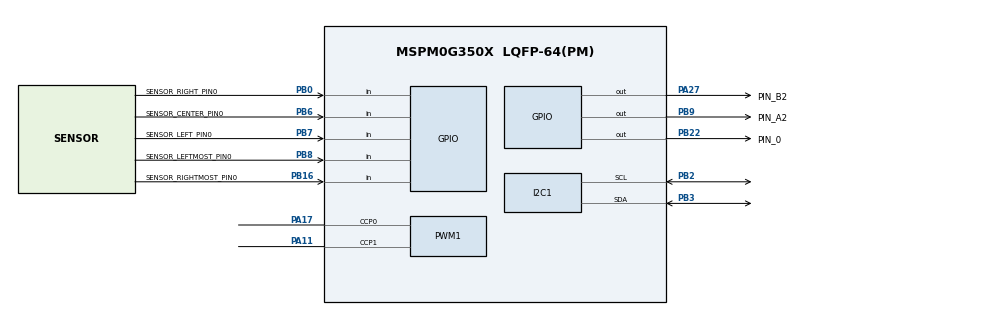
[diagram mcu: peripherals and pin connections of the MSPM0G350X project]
/**
 * @cliArgs --device "MSPM0G350X" --part "Default" --package "LQFP-64(PM)" --product "mspm0_sdk@2.05.01.00"
 * @versions {"tool":"1.24.0+4110"}
 */

/**
 * Import the modules used in this configuration.
 */
const GPIO   = scripting.addModule("/ti/driverlib/GPIO", {}, false);
const GPIO1  = GPIO.addInstance();
const GPIO2  = GPIO.addInstance();
const GPIO3  = GPIO.addInstance();
const GPIO4  = GPIO.addInstance();
const GPIO5  = GPIO.addInstance();
const GPIO6  = GPIO.addInstance();
const I2C    = scripting.addModule("/ti/driverlib/I2C", {}, false);
const I2C1   = I2C.addInstance();
const PWM    = scripting.addModule("/ti/driverlib/PWM", {}, false);
const PWM1   = PWM.addInstance();
const SYSCTL = scripting.addModule("/ti/driverlib/SYSCTL");

/**
 * Write custom configuration values to the imported modules.
 */
const divider7       = system.clockTree["PLL_PDIV"];
divider7.divideValue = 2;

const divider9       = system.clockTree["UDIV"];
divider9.divideValue = 2;

const multiplier2         = system.clockTree["PLL_QDIV"];
multiplier2.multiplyValue = 5;

const mux8       = system.clockTree["HSCLKMUX"];
mux8.inputSelect = "HSCLKMUX_SYSPLL2X";

GPIO1.$name                          = "GPIO_LED";
GPIO1.associatedPins[0].$name        = "PIN_0";
GPIO1.associatedPins[0].assignedPort = "PORTB";
GPIO1.associatedPins[0].assignedPin  = "22";
GPIO1.associatedPins[0].pin.$assign  = "PB22";

const Board = scripting.addModule("/ti/driverlib/Board", {}, false);

GPIO2.$name                          = "GPIO_SENSOR";
GPIO2.associatedPins.create(5);
GPIO2.associatedPins[0].direction    = "INPUT";
GPIO2.associatedPins[0].$name        = "SENSOR_LEFTMOST_PIN0";
GPIO2.associatedPins[0].assignedPort = "PORTB";
GPIO2.associatedPins[0].assignedPin  = "8";
GPIO2.associatedPins[0].pin.$assign  = "PB8";
GPIO2.associatedPins[1].direction    = "INPUT";
GPIO2.associatedPins[1].$name        = "SENSOR_LEFT_PIN0";
GPIO2.associatedPins[1].assignedPort = "PORTB";
GPIO2.associatedPins[1].assignedPin  = "7";
GPIO2.associatedPins[1].pin.$assign  = "PB7";
GPIO2.associatedPins[2].direction    = "INPUT";
GPIO2.associatedPins[2].$name        = "SENSOR_CENTER_PIN0";
GPIO2.associatedPins[2].assignedPort = "PORTB";
GPIO2.associatedPins[2].assignedPin  = "6";
GPIO2.associatedPins[2].pin.$assign  = "PB6";
GPIO2.associatedPins[3].$name        = "SENSOR_RIGHT_PIN0";
GPIO2.associatedPins[3].direction    = "INPUT";
GPIO2.associatedPins[3].assignedPort = "PORTB";
GPIO2.associatedPins[3].assignedPin  = "0";
GPIO2.associatedPins[3].pin.$assign  = "PB0";
GPIO2.associatedPins[4].direction    = "INPUT";
GPIO2.associatedPins[4].$name        = "SENSOR_RIGHTMOST_PIN0";
GPIO2.associatedPins[4].assignedPort = "PORTB";
GPIO2.associatedPins[4].assignedPin  = "16";
GPIO2.associatedPins[4].pin.$assign  = "PB16";

GPIO3.$name                          = "GPIO_ENCODER_L";
GPIO3.associatedPins.create(2);
GPIO3.associatedPins[0].$name        = "PIN_A1";
GPIO3.associatedPins[0].assignedPort = "PORTA";
GPIO3.associatedPins[0].assignedPin  = "26";
GPIO3.associatedPins[1].$name        = "PIN_B1";
GPIO3.associatedPins[1].assignedPort = "PORTB";
GPIO3.associatedPins[1].assignedPin  = "24";

GPIO4.$name                          = "GPIO_ENCODER_R";
GPIO4.associatedPins.create(2);
GPIO4.associatedPins[0].$name        = "PIN_A2";
GPIO4.associatedPins[0].assignedPort = "PORTB";
GPIO4.associatedPins[0].assignedPin  = "9";
GPIO4.associatedPins[0].pin.$assign  = "PB9";
GPIO4.associatedPins[1].$name        = "PIN_B2";
GPIO4.associatedPins[1].assignedPort = "PORTA";
GPIO4.associatedPins[1].assignedPin  = "27";
GPIO4.associatedPins[1].pin.$assign  = "PA27";

GPIO5.$name                          = "GPIO_6612";
GPIO5.associatedPins.create(5);
GPIO5.associatedPins[0].$name        = "AIN_2";
GPIO5.associatedPins[0].assignedPort = "PORTA";
GPIO5.associatedPins[0].assignedPin  = "28";
GPIO5.associatedPins[1].$name        = "AIN_1";
GPIO5.associatedPins[1].assignedPort = "PORTA";
GPIO5.associatedPins[1].assignedPin  = "31";
GPIO5.associatedPins[2].$name        = "STBY";
GPIO5.associatedPins[2].assignedPort = "PORTB";
GPIO5.associatedPins[2].initialValue = "SET";
GPIO5.associatedPins[2].assignedPin  = "12";
GPIO5.associatedPins[3].$name        = "BIN_1";
GPIO5.associatedPins[3].assignedPort = "PORTA";
GPIO5.associatedPins[3].assignedPin  = "12";
GPIO5.associatedPins[4].$name        = "BIN_2";
GPIO5.associatedPins[4].assignedPort = "PORTA";
GPIO5.associatedPins[4].assignedPin  = "13";

GPIO6.$name                              = "GPIO_BUTTON";
GPIO6.associatedPins.create(2);
GPIO6.associatedPins[0].$name            = "PIN_1";
GPIO6.associatedPins[0].direction        = "INPUT";
GPIO6.associatedPins[0].assignedPort     = "PORTB";
GPIO6.associatedPins[0].assignedPin      = "21";
GPIO6.associatedPins[0].internalResistor = "PULL_UP";
GPIO6.associatedPins[1].$name            = "PIN_2";
GPIO6.associatedPins[1].direction        = "INPUT";
GPIO6.associatedPins[1].internalResistor = "PULL_UP";
GPIO6.associatedPins[1].assignedPort     = "PORTA";
GPIO6.associatedPins[1].assignedPin      = "18";

I2C1.$name                             = "I2C_OLED";
I2C1.basicEnableController             = true;
I2C1.basicControllerStandardBusSpeed   = "Fast";
I2C1.peripheral.sdaPin.$assign         = "PB3";
I2C1.peripheral.sclPin.$assign         = "PB2";
I2C1.sdaPinConfig.$name                = "ti_driverlib_gpio_GPIOPinGeneric0";
I2C1.sdaPinConfig.hideOutputInversion  = scripting.forceWrite(false);
I2C1.sdaPinConfig.onlyInternalResistor = scripting.forceWrite(false);
I2C1.sdaPinConfig.passedPeripheralType = scripting.forceWrite("Digital");
I2C1.sclPinConfig.$name                = "ti_driverlib_gpio_GPIOPinGeneric1";
I2C1.sclPinConfig.hideOutputInversion  = scripting.forceWrite(false);
I2C1.sclPinConfig.onlyInternalResistor = scripting.forceWrite(false);
I2C1.sclPinConfig.passedPeripheralType = scripting.forceWrite("Digital");

PWM1.$name                              = "PWM_WHEEL";
PWM1.timerStartTimer                    = true;
PWM1.timerCount                         = 8000;
PWM1.peripheral.$assign                 = "TIMA1";
PWM1.peripheral.ccp0Pin.$assign         = "PA17";
PWM1.peripheral.ccp1Pin.$assign         = "PA11";
PWM1.PWM_CHANNEL_0.$name                = "ti_driverlib_pwm_PWMTimerCC0";
PWM1.PWM_CHANNEL_0.dutyCycle            = 50;
PWM1.PWM_CHANNEL_1.$name                = "ti_driverlib_pwm_PWMTimerCC1";
PWM1.PWM_CHANNEL_1.dutyCycle            = 50;
PWM1.ccp0PinConfig.$name                = "ti_driverlib_gpio_GPIOPinGeneric2";
PWM1.ccp0PinConfig.direction            = scripting.forceWrite("OUTPUT");
PWM1.ccp0PinConfig.hideOutputInversion  = scripting.forceWrite(false);
PWM1.ccp0PinConfig.onlyInternalResistor = scripting.forceWrite(false);
PWM1.ccp0PinConfig.passedPeripheralType = scripting.forceWrite("Digital");
PWM1.ccp1PinConfig.$name                = "ti_driverlib_gpio_GPIOPinGeneric3";
PWM1.ccp1PinConfig.direction            = scripting.forceWrite("OUTPUT");
PWM1.ccp1PinConfig.hideOutputInversion  = scripting.forceWrite(false);
PWM1.ccp1PinConfig.onlyInternalResistor = scripting.forceWrite(false);
PWM1.ccp1PinConfig.passedPeripheralType = scripting.forceWrite("Digital");

SYSCTL.forceDefaultClkConfig = true;
SYSCTL.clockTreeEn           = true;
scripting.suppress("For best practices when the CPUCLK is running at 32MHz and above, clear the flash status bit using DL_FlashCTL_executeClearStatus\\(\\) before executing any flash operation\\. Otherwise there may be false positives\\.", SYSCTL);

/**
 * Pinmux solution for unlocked pins/peripherals. This ensures that minor changes to the automatic solver in a future
 * version of the tool will not impact the pinmux you originally saw.  These lines can be completely deleted in order to
 * re-solve from scratch.
 */
Board.peripheral.$suggestSolution            = "DEBUGSS";
Board.peripheral.swclkPin.$suggestSolution   = "PA20";
Board.peripheral.swdioPin.$suggestSolution   = "PA19";
GPIO3.associatedPins[0].pin.$suggestSolution = "PA26";
GPIO3.associatedPins[1].pin.$suggestSolution = "PB24";
GPIO5.associatedPins[0].pin.$suggestSolution = "PA28";
GPIO5.associatedPins[1].pin.$suggestSolution = "PA31";
GPIO5.associatedPins[2].pin.$suggestSolution = "PB12";
GPIO5.associatedPins[3].pin.$suggestSolution = "PA12";
GPIO5.associatedPins[4].pin.$suggestSolution = "PA13";
GPIO6.associatedPins[0].pin.$suggestSolution = "PB21";
GPIO6.associatedPins[1].pin.$suggestSolution = "PA18";
I2C1.peripheral.$suggestSolution             = "I2C1";
